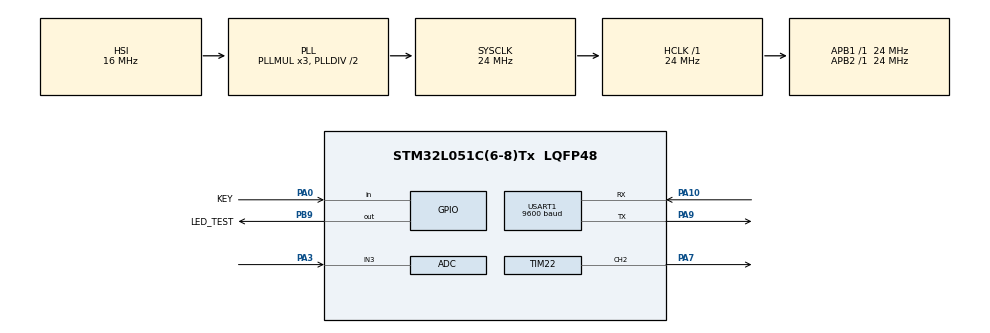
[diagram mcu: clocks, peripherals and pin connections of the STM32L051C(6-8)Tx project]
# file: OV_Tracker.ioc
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Dma.Request0=USART1_RX
Dma.Request1=USART1_TX
Dma.USART1_RX.0.Direction=DMA_PERIPH_TO_MEMORY
Dma.USART1_RX.0.Instance=DMA1_Channel3
Dma.USART1_RX.0.MemDataAlignment=DMA_MDATAALIGN_BYTE
Dma.USART1_RX.0.MemInc=DMA_MINC_ENABLE
Dma.USART1_RX.0.Mode=DMA_NORMAL
Dma.USART1_RX.0.PeriphDataAlignment=DMA_PDATAALIGN_BYTE
Dma.USART1_RX.0.PeriphInc=DMA_PINC_DISABLE
Dma.USART1_RX.0.Priority=DMA_PRIORITY_LOW
Dma.USART1_TX.1.Direction=DMA_MEMORY_TO_PERIPH
Dma.USART1_TX.1.Instance=DMA1_Channel2
Dma.USART1_TX.1.MemDataAlignment=DMA_MDATAALIGN_BYTE
Dma.USART1_TX.1.MemInc=DMA_MINC_ENABLE
Dma.USART1_TX.1.Mode=DMA_NORMAL
Dma.USART1_TX.1.PeriphDataAlignment=DMA_PDATAALIGN_BYTE
Dma.USART1_TX.1.PeriphInc=DMA_PINC_DISABLE
Dma.USART1_TX.1.Priority=DMA_PRIORITY_LOW
FREERTOS.Tasks01=defaultTask,24,128,StartDefaultTask,Default,NULL,Dynamic,NULL,NULL
FREERTOS.configTOTAL_HEAP_SIZE=2048
Mcu.Family=STM32L0
Mcu.Name=STM32L051C(6-8)Tx
Mcu.Package=LQFP48
NVIC.DMA1_Channel2_3_IRQn=true\:3\:0\:false\:false\:true\:true\:false\:true\:true
NVIC.RTC_IRQn=true\:3\:0\:false\:false\:true\:true\:true\:true\:true
NVIC.TIM21_IRQn=true\:3\:0\:false\:false\:true\:false\:false\:true\:true
NVIC.TimeBase=TIM21_IRQn
NVIC.TimeBaseIP=TIM21
NVIC.USART1_IRQn=true\:3\:0\:false\:false\:true\:true\:true\:true\:true
PA0.GPIO_Label=KEY
PA0.GPIO_PuPd=GPIO_PULLUP
PA0.Signal=GPIO_Input
PA10.Mode=Asynchronous
PA10.Signal=USART1_RX
PA13.Mode=Serial_Wire
PA13.Signal=SYS_SWDIO
PA14.Mode=Serial_Wire
PA14.Signal=SYS_SWCLK
PA3.Mode=IN3
PA3.Signal=ADC_IN3
PA7.Signal=S_TIM22_CH2
PA9.Mode=Asynchronous
PA9.Signal=USART1_TX
PB9.GPIO_Label=LED_TEST
PB9.Signal=GPIO_Output
PC14-OSC32_IN.Mode=LSE-External-Oscillator
PC14-OSC32_IN.Signal=RCC_OSC32_IN
PC15-OSC32_OUT.Mode=LSE-External-Oscillator
PC15-OSC32_OUT.Signal=RCC_OSC32_OUT
ProjectManager.HeapSize=0x200
ProjectManager.StackSize=0x400
ProjectManager.TargetToolchain=MDK-ARM V5.32
RCC.AHBFreq_Value=24000000
RCC.APB1Freq_Value=24000000
RCC.APB1TimFreq_Value=24000000
RCC.APB2Freq_Value=24000000
RCC.APB2TimFreq_Value=24000000
RCC.HCLKFreq_Value=24000000
RCC.HSE_VALUE=8000000
RCC.HSI16_VALUE=16000000
RCC.HSI_VALUE=16000000
RCC.MSI_VALUE=2097000
RCC.RTCClockSelection=RCC_RTCCLKSOURCE_LSE
RCC.RTCClockSelectionVirtual=RCC_RTCCLKSOURCE_LSE
RCC.SYSCLKFreq_VALUE=24000000
RCC.SYSCLKSource=RCC_SYSCLKSOURCE_PLLCLK
RCC.VCOOutputFreq_Value=48000000
RTC.WakeUpClock-WakeUp=RTC_WAKEUPCLOCK_CK_SPRE_16BITS
RTC.WakeUpCounter-WakeUp=1
SH.S_TIM22_CH2.0=TIM22_CH2,PWM Generation2 CH2
TIM22.Channel-PWM\ Generation2\ CH2=TIM_CHANNEL_2
TIM22.Period=369
TIM22.Prescaler=23
TIM22.Pulse-PWM\ Generation2\ CH2=185
USART1.BaudRate=9600
USART1.VirtualMode-Asynchronous=VM_ASYNC
VP_FREERTOS_VS_CMSIS_V2.Mode=CMSIS_V2
VP_IWDG_VS_IWDG.Mode=IWDG_Activate
VP_RTC_VS_RTC_Activate.Mode=RTC_Enabled
VP_RTC_VS_RTC_WakeUp_intern.Mode=WakeUp
VP_SYS_VS_tim21.Mode=TIM21
board=custom

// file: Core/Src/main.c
/* USER CODE BEGIN Header */
/**
  ******************************************************************************
  * @file           : main.c
  * @brief          : Main program body
  ******************************************************************************
  * @attention
  *
  * Copyright (c) 2024 STMicroelectronics.
  * All rights reserved.
  *
  * This software is licensed under terms that can be found in the LICENSE file
  * in the root directory of this software component.
  * If no LICENSE file comes with this software, it is provided AS-IS.
  *
  ******************************************************************************
  */
/* USER CODE END Header */
#include "main.h"
#include "cmsis_os.h"
#include "adc.h"
#include "dma.h"
#include "iwdg.h"
#include "rtc.h"
#include "tim.h"
#include "usart.h"
#include "gpio.h"

/* USER CODE BEGIN Includes */
#include "delay.h"
#include "beep.h"
/* USER CODE END Includes */

void SystemClock_Config(void);
void MX_FREERTOS_Init(void);

int main(void)
{

  /* MCU Configuration--------------------------------------------------------*/

  /* Reset of all peripherals, Initializes the Flash interface and the Systick. */
  HAL_Init();

  /* Configure the system clock */
  SystemClock_Config();

  /* Initialize all configured peripherals */
  MX_GPIO_Init();
  MX_DMA_Init();
  MX_ADC_Init();
//  MX_IWDG_Init();
  MX_RTC_Init();
  MX_TIM22_Init();
  MX_USART1_UART_Init();
  /* USER CODE BEGIN 2 */

	HAL_UART_Receive_DMA(&huart1,(uint8_t*)HardInt_receive_str_raw, 120);
	__HAL_UART_ENABLE_IT(&huart1, UART_IT_IDLE);

  /* USER CODE END 2 */

  /* Init scheduler */
  osKernelInitialize();  /* Call init function for freertos objects (in freertos.c) */
  MX_FREERTOS_Init();

  /* Start scheduler */
  osKernelStart();

  /* We should never get here as control is now taken by the scheduler */
  /* Infinite loop */
  while (1)
  {

  }
}

void SystemClock_Config(void)
{
  RCC_OscInitTypeDef RCC_OscInitStruct = {0};
  RCC_ClkInitTypeDef RCC_ClkInitStruct = {0};
  RCC_PeriphCLKInitTypeDef PeriphClkInit = {0};

  /** Configure the main internal regulator output voltage
  */
  __HAL_PWR_VOLTAGESCALING_CONFIG(PWR_REGULATOR_VOLTAGE_SCALE1);

  /** Configure LSE Drive Capability
  */
  HAL_PWR_EnableBkUpAccess();
  __HAL_RCC_LSEDRIVE_CONFIG(RCC_LSEDRIVE_LOW);

  /** Initializes the RCC Oscillators according to the specified parameters
  * in the RCC_OscInitTypeDef structure.
  */
  RCC_OscInitStruct.OscillatorType = RCC_OSCILLATORTYPE_HSI|RCC_OSCILLATORTYPE_LSI
                              |RCC_OSCILLATORTYPE_LSE;
  RCC_OscInitStruct.LSEState = RCC_LSE_ON;
  RCC_OscInitStruct.HSIState = RCC_HSI_ON;
  RCC_OscInitStruct.HSICalibrationValue = RCC_HSICALIBRATION_DEFAULT;
  RCC_OscInitStruct.LSIState = RCC_LSI_ON;
  RCC_OscInitStruct.PLL.PLLState = RCC_PLL_ON;
  RCC_OscInitStruct.PLL.PLLSource = RCC_PLLSOURCE_HSI;
  RCC_OscInitStruct.PLL.PLLMUL = RCC_PLLMUL_3;
  RCC_OscInitStruct.PLL.PLLDIV = RCC_PLLDIV_2;
  if (HAL_RCC_OscConfig(&RCC_OscInitStruct) != HAL_OK)
  {
    Error_Handler();
  }

  /** Initializes the CPU, AHB and APB buses clocks
  */
  RCC_ClkInitStruct.ClockType = RCC_CLOCKTYPE_HCLK|RCC_CLOCKTYPE_SYSCLK
                              |RCC_CLOCKTYPE_PCLK1|RCC_CLOCKTYPE_PCLK2;
  RCC_ClkInitStruct.SYSCLKSource = RCC_SYSCLKSOURCE_PLLCLK;
  RCC_ClkInitStruct.AHBCLKDivider = RCC_SYSCLK_DIV1;
  RCC_ClkInitStruct.APB1CLKDivider = RCC_HCLK_DIV1;
  RCC_ClkInitStruct.APB2CLKDivider = RCC_HCLK_DIV1;

  if (HAL_RCC_ClockConfig(&RCC_ClkInitStruct, FLASH_LATENCY_1) != HAL_OK)
  {
    Error_Handler();
  }
  PeriphClkInit.PeriphClockSelection = RCC_PERIPHCLK_USART1|RCC_PERIPHCLK_RTC;
  PeriphClkInit.Usart1ClockSelection = RCC_USART1CLKSOURCE_PCLK2;
  PeriphClkInit.RTCClockSelection = RCC_RTCCLKSOURCE_LSE;
  if (HAL_RCCEx_PeriphCLKConfig(&PeriphClkInit) != HAL_OK)
  {
    Error_Handler();
  }
}

void HAL_TIM_PeriodElapsedCallback(TIM_HandleTypeDef *htim)
{
  if (htim->Instance == TIM21) {
    HAL_IncTick();
  }
}

void Error_Handler(void)
{
  __disable_irq();
  while (1)
  {
  }
}

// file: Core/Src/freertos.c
/* USER CODE BEGIN Header */
/**
  ******************************************************************************
  * File Name          : freertos.c
  * Description        : Code for freertos applications
  ******************************************************************************
  * @attention
  *
  * Copyright (c) 2024 STMicroelectronics.
  * All rights reserved.
  *
  * This software is licensed under terms that can be found in the LICENSE file
  * in the root directory of this software component.
  * If no LICENSE file comes with this software, it is provided AS-IS.
  *
  ******************************************************************************
  */
/* USER CODE END Header */

#include "FreeRTOS.h"
#include "task.h"
#include "main.h"
#include "cmsis_os.h"

/* USER CODE BEGIN Includes */
#include "user_TasksInit.h"
/* USER CODE END Includes */

/* Definitions for defaultTask */
osThreadId_t defaultTaskHandle;
const osThreadAttr_t defaultTask_attributes = {
  .name = "defaultTask",
  .stack_size = 128 * 4,
  .priority = (osPriority_t) osPriorityNormal,
};

void StartDefaultTask(void *argument);

void MX_FREERTOS_Init(void); /* (MISRA C 2004 rule 8.1) */

void MX_FREERTOS_Init(void) {
  /* USER CODE BEGIN Init */
	User_Tasks_Init();
  /* USER CODE END Init */

  /* Create the thread(s) */
  /* creation of defaultTask */
  defaultTaskHandle = osThreadNew(StartDefaultTask, NULL, &defaultTask_attributes);

}

void StartDefaultTask(void *argument)
{
  for(;;)
  {
    osDelay(1);
  }
}
